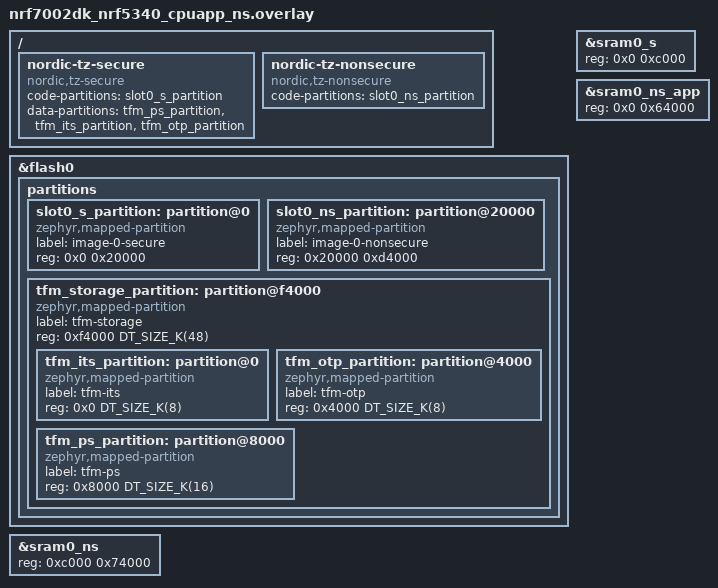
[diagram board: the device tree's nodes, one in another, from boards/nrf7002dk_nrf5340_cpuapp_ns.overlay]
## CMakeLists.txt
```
#
# Copyright (c) 2020 Nordic Semiconductor
#
# SPDX-License-Identifier: LicenseRef-Nordic-5-Clause
#

cmake_minimum_required(VERSION 3.20.0)

find_package(Zephyr REQUIRED HINTS $ENV{ZEPHYR_BASE})
project(https_client)

# Generate hex files from pem files
set(gen_dir ${CMAKE_CURRENT_BINARY_DIR}/certs)
zephyr_include_directories(${gen_dir})
generate_inc_file_for_target(
    app
    cert/example_com_ca.pem
    ${gen_dir}/example_com_ca.pem.inc
    )

# NORDIC SDK APP START
target_sources(app PRIVATE src/main.c)
# NORDIC SDK APP END
```

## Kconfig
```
#
# Copyright (c) 2021 Nordic Semiconductor ASA
#
# SPDX-License-Identifier: LicenseRef-Nordic-5-Clause
#

menu "HTTPS client sample"

config SAMPLE_TFM_MBEDTLS
	bool "Use TF-M and MbedTLS"
	depends on NRF_MODEM_LIB
	help
	  Use TF-M and MbedTLS in this sample instead of using
	  the offloaded TLS stack in the modem.

config HTTPS_HOSTNAME
	string "HTTPS hostname"
	default "example.com"

endmenu

# Default the TLS credentials backend by build type: NS builds use Protected
# Storage, secure-only builds fall back to the volatile backend. nRF91 keeps
# its own NRF_MODEM backend default.
choice TLS_CREDENTIALS_BACKEND
	default TLS_CREDENTIALS_BACKEND_PROTECTED_STORAGE if BUILD_WITH_TFM && !NRF_MODEM_LIB
endchoice

menu "Zephyr Kernel"
source "Kconfig.zephyr"
endmenu
```

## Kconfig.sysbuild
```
#
# Copyright (c) 2024 Nordic Semiconductor ASA
#
# SPDX-License-Identifier: LicenseRef-Nordic-5-Clause
#

config WIFI_NRF70
	default y if BOARD_NRF7002DK_NRF5340_CPUAPP_NS || \
		BOARD_NRF54L15DK_NRF54L15_CPUAPP || \
		BOARD_NRF54H20DK_NRF54H20_CPUAPP || \
		BOARD_NRF54LM20DK_NRF54LM20A_CPUAPP || \
		BOARD_NRF54LM20DK_NRF54LM20B_CPUAPP

source "share/sysbuild/Kconfig"
```

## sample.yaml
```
sample:
  name: HTTPS client sample
tests:
  sample.net.https_client:
    sysbuild: true
    build_only: true
    integration_platforms:
      - nrf9151dk/nrf9151/ns
      - native_sim
    platform_allow:
      - nrf9151dk/nrf9151/ns
      - native_sim
    tags:
      - ci_build
      - sysbuild
      - ci_samples_net
  sample.net.https_client.wifi:
    sysbuild: true
    build_only: true
    integration_platforms:
      - nrf7002dk/nrf5340/cpuapp/ns
      - nrf7120dk/nrf7120/cpuapp/ns
    platform_allow:
      - nrf7002dk/nrf5340/cpuapp/ns
      - nrf7120dk/nrf7120/cpuapp/ns
    tags:
      - ci_build
      - sysbuild
      - ci_samples_net
    extra_args:
      - https_client_EXTRA_CONF_FILE="wifi.conf"
  sample.net.https_client.lte.tfm-mbedtls:
    sysbuild: true
    build_only: true
    extra_args: EXTRA_CONF_FILE="overlay-tfm-nrf91.conf"
    integration_platforms:
      - nrf9151dk/nrf9151/ns
    platform_allow:
      - nrf9151dk/nrf9151/ns
    tags:
      - ci_build
      - sysbuild
      - ci_samples_net
  sample.net.https_client.lte.pdn-ipv4:
    sysbuild: true
    build_only: true
    extra_args: EXTRA_CONF_FILE="overlay-pdn-nrf91-ipv4.conf"
    integration_platforms:
      - nrf9151dk/nrf9151/ns
    platform_allow:
      - nrf9151dk/nrf9151/ns
    tags:
      - ci_build
      - sysbuild
      - ci_samples_net
  sample.net.https_client.nrf54l15_nrf7002eb2.wifi:
    sysbuild: true
    build_only: true
    integration_platforms:
      - nrf54l15dk/nrf54l15/cpuapp
    platform_allow:
      - nrf54l15dk/nrf54l15/cpuapp
    tags:
      - ci_build
      - sysbuild
      - ci_samples_net
    extra_args:
      - https_client_SHIELD="nrf7002eb2"
      - https_client_SNIPPET="nrf70-wifi;wifi-credentials"
      - https_client_EXTRA_CONF_FILE="wifi.conf"
  sample.net.https_client.nrf54lm20_nrf7002eb2.wifi:
    sysbuild: true
    build_only: true
    integration_platforms:
      - nrf54lm20dk/nrf54lm20a/cpuapp
      - nrf54lm20dk/nrf54lm20b/cpuapp
    platform_allow:
      - nrf54lm20dk/nrf54lm20a/cpuapp
      - nrf54lm20dk/nrf54lm20b/cpuapp
    tags:
      - ci_build
      - sysbuild
      - ci_samples_net
    extra_args:
      - https_client_SHIELD="nrf7002eb2"
      - https_client_SNIPPET=wifi-credentials
      - https_client_EXTRA_CONF_FILE="wifi.conf"
```

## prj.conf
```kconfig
#
# Copyright (c) 2023 Nordic Semiconductor ASA
#
# SPDX-License-Identifier: LicenseRef-Nordic-5-Clause
#

# General
CONFIG_HEAP_MEM_POOL_SIZE=1280
CONFIG_MAIN_STACK_SIZE=4096

# Logging
CONFIG_LOG=y

# Network
CONFIG_NETWORKING=y
CONFIG_NET_SOCKETS=y
CONFIG_POSIX_API=y
CONFIG_NET_IPV4=y
CONFIG_NET_IPV6=y
CONFIG_NET_CONNECTION_MANAGER=y
```

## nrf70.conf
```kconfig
#
# Copyright (c) 2026 Nordic Semiconductor ASA
#
# SPDX-License-Identifier: LicenseRef-Nordic-5-Clause
#

# nRF70 Wi-Fi driver tuning (external nRF7002 companion). Kept out of wifi.conf so it is
# only applied on nRF70 targets; the integrated nRF71 (nrf7120) uses its board conf instead.
CONFIG_NRF70_RX_NUM_BUFS=16
CONFIG_NRF70_MAX_TX_AGGREGATION=4
CONFIG_NRF70_BH_WQ_STACK_SIZE=2300
```

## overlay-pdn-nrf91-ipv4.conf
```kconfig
#
# Copyright (c) 2023 Nordic Semiconductor ASA
#
# SPDX-License-Identifier: LicenseRef-Nordic-5-Clause
#

CONFIG_LTE_LC_PDN_DEFAULTS_OVERRIDE=y
CONFIG_LTE_LC_PDN_DEFAULT_FAM_IPV4=y
```

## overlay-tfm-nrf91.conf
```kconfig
#
# Copyright (c) 2023 Nordic Semiconductor ASA
#
# SPDX-License-Identifier: LicenseRef-Nordic-5-Clause
#

CONFIG_SAMPLE_TFM_MBEDTLS=y

# TFM configuration
CONFIG_TFM_PROFILE_TYPE_NOT_SET=y

# MbedTLS and security
CONFIG_MBEDTLS=y
CONFIG_NET_SOCKETS_SOCKOPT_TLS=y
CONFIG_MBEDTLS_ENABLE_HEAP=y
CONFIG_MBEDTLS_SSL_IN_CONTENT_LEN=4096
CONFIG_MBEDTLS_SSL_OUT_CONTENT_LEN=4096
CONFIG_MBEDTLS_SSL_SERVER_NAME_INDICATION=y
CONFIG_MBEDTLS_HEAP_SIZE=32768
CONFIG_MBEDTLS_DECLARE_PRIVATE_IDENTIFIERS=y
CONFIG_MBEDTLS_MD_C=y
CONFIG_MBEDTLS_HMAC_DRBG_C=y
CONFIG_PSA_WANT_ALG_SHA_256=y
CONFIG_PSA_WANT_KEY_TYPE_ECC_KEY_PAIR_IMPORT=y
CONFIG_PSA_WANT_KEY_TYPE_ECC_KEY_PAIR_EXPORT=y
CONFIG_PSA_WANT_KEY_TYPE_ECC_KEY_PAIR_GENERATE=y
CONFIG_PSA_WANT_KEY_TYPE_ECC_KEY_PAIR_DERIVE=y
CONFIG_MBEDTLS_CTR_DRBG_C=y
CONFIG_PSA_WANT_KEY_TYPE_AES=y
CONFIG_PSA_WANT_ALG_CBC_PKCS7=y
CONFIG_PSA_WANT_ALG_CBC_NO_PADDING=y
CONFIG_PSA_WANT_ALG_CTR=y
CONFIG_MBEDTLS_ENTROPY_C=y

CONFIG_PSA_WANT_ALG_RSA_PKCS1V15_CRYPT=y
CONFIG_PSA_WANT_ALG_RSA_PKCS1V15_SIGN=y
CONFIG_PSA_WANT_ALG_RSA_PSS=y
CONFIG_PSA_WANT_ALG_RSA_OAEP=y
CONFIG_PSA_WANT_RSA_KEY_SIZE_2048=y
CONFIG_PSA_WANT_KEY_TYPE_RSA_KEY_PAIR_IMPORT=y
CONFIG_PSA_WANT_KEY_TYPE_RSA_KEY_PAIR_EXPORT=y
CONFIG_PSA_WANT_KEY_TYPE_RSA_KEY_PAIR_DERIVE=y
CONFIG_PSA_WANT_KEY_TYPE_RSA_KEY_PAIR_GENERATE=y

CONFIG_MBEDTLS_PEM_PARSE_C=y
CONFIG_PSA_WANT_KEY_TYPE_RSA_KEY_PAIR_IMPORT=y
CONFIG_PSA_WANT_KEY_TYPE_RSA_KEY_PAIR_EXPORT=y
CONFIG_PSA_WANT_KEY_TYPE_RSA_KEY_PAIR_GENERATE=y
# Set MPI (Multiple Precision Integer) size limit to 512 bytes for handling of 4 kb certificates
# in cryptographic operations.
CONFIG_MBEDTLS_MPI_MAX_SIZE=512
# ECDH/ECDSA are needed for TLS handshake
CONFIG_PSA_WANT_ALG_ECDH=y
CONFIG_PSA_WANT_ALG_ECDSA=y
CONFIG_PSA_CRYPTO=y
CONFIG_PSA_CRYPTO_DRIVER_CC3XX=y
# The CC3xx (CryptoCell) PSA driver fails ECDSA *verification* of an imported
# public key (returns PSA_ERROR_INVALID_ARGUMENT), which breaks TLS certificate
# and ServerKeyExchange verification. Disable the CC3xx asymmetric-signature
# driver so ECDSA verify is serviced by the Oberon software driver instead.
CONFIG_PSA_USE_CC3XX_ASYMMETRIC_SIGNATURE_DRIVER=n
CONFIG_PSA_WANT_ALG_SHA_1=y
# SHA-384 is required to verify the ecdsa-with-SHA384 signature on the
# intermediate CA in example.com's chain (and for AES_256_GCM_SHA384 PRF)
CONFIG_PSA_WANT_ALG_SHA_384=y
CONFIG_PSA_WANT_ALG_RSA_PKCS1V15_CRYPT=y
CONFIG_PSA_WANT_ALG_RSA_PKCS1V15_SIGN=y
CONFIG_PSA_WANT_KEY_TYPE_RSA_PUBLIC_KEY=y
CONFIG_PSA_WANT_ECC_SECP_R1_256=y
CONFIG_PSA_WANT_ECC_SECP_R1_384=y

# RSA requires that at least one key size is enabled
CONFIG_PSA_WANT_RSA_KEY_SIZE_1024=y

# Modem key management needs to be set to n, if not the certificate are provisioned to the modem
CONFIG_MODEM_KEY_MGMT=n
```

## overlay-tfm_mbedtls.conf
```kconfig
#
# Copyright (c) 2023 Nordic Semiconductor ASA
#
# SPDX-License-Identifier: LicenseRef-Nordic-5-Clause
#

CONFIG_SAMPLE_TFM_MBEDTLS=y

# TFM configuration
CONFIG_TFM_PROFILE_TYPE_NOT_SET=y

# MbedTLS and security
CONFIG_MBEDTLS=y
CONFIG_NET_SOCKETS_SOCKOPT_TLS=y
CONFIG_MBEDTLS_ENABLE_HEAP=y
CONFIG_MBEDTLS_SSL_IN_CONTENT_LEN=4096
CONFIG_MBEDTLS_SSL_OUT_CONTENT_LEN=4096
CONFIG_MBEDTLS_HEAP_SIZE=32768
CONFIG_MBEDTLS_RSA_C=y
CONFIG_MBEDTLS_TLS_LIBRARY=y
CONFIG_MBEDTLS_X509_LIBRARY=y
CONFIG_MBEDTLS_PKCS1_V15=y
CONFIG_NRF_SECURITY_ADVANCED=y
CONFIG_NORDIC_SECURITY_BACKEND=y
CONFIG_PSA_CRYPTO_DRIVER_CC3XX=y
CONFIG_PSA_WANT_ALG_SHA_1=y
CONFIG_PSA_WANT_ALG_RSA_PKCS1V15_CRYPT=y
CONFIG_PSA_WANT_ALG_RSA_PKCS1V15_SIGN=y
CONFIG_PSA_WANT_KEY_TYPE_RSA_PUBLIC_KEY=y

# RSA requires that at least one key size is enabled
CONFIG_PSA_WANT_RSA_KEY_SIZE_1024=y

# Modem key management needs to be set to n, if not the certificate are provisioned to the modem
CONFIG_MODEM_KEY_MGMT=n
```

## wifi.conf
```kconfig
#
# Copyright (c) 2026 Nordic Semiconductor ASA
#
# SPDX-License-Identifier: LicenseRef-Nordic-5-Clause
#

# Common Wi-Fi + networking + TLS configuration shared by all Wi-Fi builds of
# this sample (nRF70 and nRF71).

# Logging
CONFIG_NET_LOG=y

# Wi-Fi stack
CONFIG_WIFI=y
CONFIG_WIFI_NM_WPA_SUPPLICANT=y
CONFIG_NET_L2_ETHERNET=y

# Wi-Fi credentials. TF-M (_ns) builds use PSA Protected Storage. Non-TF-M
# builds use the Settings subsystem, requiring the wifi-credentials snippet.
CONFIG_WIFI_CREDENTIALS=y

# Zephyr NET Connection Manager Connectivity layer.
CONFIG_L2_WIFI_CONNECTIVITY=y
CONFIG_L2_WIFI_CONNECTIVITY_AUTO_CONNECT=n
CONFIG_L2_WIFI_CONNECTIVITY_AUTO_DOWN=n

# Networking
CONFIG_NET_NATIVE=y
CONFIG_NET_SOCKETS=y
CONFIG_NET_SOCKETS_OFFLOAD=n
CONFIG_NET_IPV6=y
CONFIG_NET_UDP=y
CONFIG_NET_TCP=y
CONFIG_NET_DHCPV4=y
CONFIG_NET_CONTEXT_SNDTIMEO=y
CONFIG_NET_CONTEXT_RCVTIMEO=y

# DNS
CONFIG_DNS_RESOLVER=y
CONFIG_NET_SOCKETS_DNS_TIMEOUT=30000
CONFIG_DNS_RESOLVER_AI_MAX_ENTRIES=4

# Wi-Fi shell
CONFIG_SHELL=y
CONFIG_SHELL_CMDS_RESIZE=n
CONFIG_NET_L2_WIFI_SHELL=y

# POSIX API memory optimizations
CONFIG_POSIX_NETWORKING=y
CONFIG_POSIX_FD_MGMT=n
CONFIG_POSIX_MESSAGE_PASSING=n
CONFIG_POSIX_THREAD_THREADS_MAX=0

# Network resource sizing (workload-specific for this sample)
CONFIG_NET_MAX_CONN=8
CONFIG_NET_MAX_CONTEXTS=6
CONFIG_ZVFS_POLL_MAX=8
CONFIG_NET_PKT_TX_COUNT=6
CONFIG_NET_PKT_RX_COUNT=6
CONFIG_NET_BUF_TX_COUNT=12
CONFIG_NET_BUF_RX_COUNT=6

# NET sockets TLS
CONFIG_NET_SOCKETS_ENABLE_DTLS=n
CONFIG_NET_SOCKETS_TLS_MAX_CONTEXTS=2
CONFIG_NET_SOCKETS_SOCKOPT_TLS=y
CONFIG_TLS_CREDENTIALS=y
# Persist TLS credentials across reboots.
CONFIG_TLS_CREDENTIALS_BACKEND_PROTECTED_STORAGE=y

# mbedTLS
CONFIG_MBEDTLS=y
CONFIG_MBEDTLS_ENABLE_HEAP=y
# Shrink the TLS record buffers and negotiate the smaller size with the peer
# (RFC 6066 max_fragment_length) so servers don't send records larger than
# what we can receive. This cuts mbedTLS's heap requirement by roughly 24KB
# (measured) without risking handshake failures against servers that send
# larger default-sized records (e.g. bigger certificate chains).
CONFIG_MBEDTLS_SSL_IN_CONTENT_LEN=4096
CONFIG_MBEDTLS_SSL_OUT_CONTENT_LEN=4096
CONFIG_MBEDTLS_SSL_MAX_FRAGMENT_LENGTH=y
CONFIG_MBEDTLS_HEAP_SIZE=49152
CONFIG_MBEDTLS_SSL_KEEP_PEER_CERTIFICATE=n
CONFIG_MBEDTLS_SSL_SERVER_NAME_INDICATION=y
CONFIG_MBEDTLS_PEM_PARSE_C=y
CONFIG_MBEDTLS_CIPHERSUITE_TLS_ECDHE_RSA_WITH_AES_128_CBC_SHA256=y
CONFIG_MBEDTLS_CIPHERSUITE_TLS_ECDHE_ECDSA_WITH_AES_256_GCM_SHA384=y
# P-384 for the example.com CA cert (EC P-384 public key). P-256 (server certs and
# ECDHE) and ECDSA sig verify are already pulled in by the ECDHE_ECDSA ciphersuite above.
CONFIG_PSA_WANT_ECC_SECP_R1_384=y
# pk_wrap.c uses PSA_ALG_ECDSA_ANY (pre-hashed ECDSA) for X.509 certificate chain
# verification; without this the PSA core rejects psa_import_key for the CA cert's
# public key and the handshake fails with MBEDTLS_ERR_SSL_FEATURE_UNAVAILABLE.
CONFIG_PSA_WANT_ALG_ECDSA=y
CONFIG_PSA_WANT_KEY_TYPE_ECC_KEY_PAIR_DERIVE=y
# PSA_WANT_ALG_CHACHA20_POLY1305 is auto-enabled (CRACEN HW). The server may pick this
# cipher; psa_import_key(PSA_KEY_TYPE_CHACHA20) then fails unless the key type is also enabled.
CONFIG_PSA_WANT_KEY_TYPE_CHACHA20=y

# Stack sizes
CONFIG_MAIN_STACK_SIZE=8192
CONFIG_SHELL_STACK_SIZE=6144
CONFIG_SYSTEM_WORKQUEUE_STACK_SIZE=4096
CONFIG_NET_CONNECTION_MANAGER_MONITOR_STACK_SIZE=5000
CONFIG_NET_TX_STACK_SIZE=4096
CONFIG_NET_RX_STACK_SIZE=4096

# Heap sizes
CONFIG_HEAP_MEM_POOL_IGNORE_MIN=y
CONFIG_HEAP_MEM_POOL_SIZE=37000
CONFIG_NRF_WIFI_DATA_HEAP_SIZE=32768

# Floating-point printf support (Wi-Fi shell prints PHY TX rate as %f)
CONFIG_CBPRINTF_FP_SUPPORT=y
```

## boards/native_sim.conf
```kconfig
#
# Copyright (c) 2024 Nordic Semiconductor ASA
#
# SPDX-License-Identifier: LicenseRef-Nordic-5-Clause
#

# Networking config
CONFIG_NETWORKING=y
CONFIG_NET_CONFIG_SETTINGS=y
CONFIG_NET_CONNECTION_MANAGER=y
CONFIG_NET_IPV4=y
CONFIG_NET_IPV6=y
CONFIG_NET_TCP=y
CONFIG_NET_UDP=y
CONFIG_NET_SOCKETS=y
CONFIG_POSIX_API=y

# TLS networking
CONFIG_NET_SOCKETS_ENABLE_DTLS=n
CONFIG_NET_SOCKETS_TLS_MAX_CONTEXTS=2
CONFIG_NET_SOCKETS_SOCKOPT_TLS=y

# TLS configuration
CONFIG_MBEDTLS=y
CONFIG_MBEDTLS_ENABLE_HEAP=y
CONFIG_MBEDTLS_HEAP_SIZE=40000
CONFIG_MBEDTLS_SSL_MAX_CONTENT_LEN=7168
CONFIG_MBEDTLS_PEM_PARSE_C=y
CONFIG_MBEDTLS_PEM_WRITE_C=y
CONFIG_MBEDTLS_CIPHERSUITE_TLS_ECDHE_RSA_WITH_AES_128_CBC_SHA256=y
CONFIG_MBEDTLS_CIPHERSUITE_TLS_ECDHE_ECDSA_WITH_AES_256_GCM_SHA384=y
CONFIG_MBEDTLS_SSL_SERVER_NAME_INDICATION=y
CONFIG_PSA_WANT_ECC_SECP_R1_384=y

# DNS
CONFIG_DNS_RESOLVER=y
CONFIG_DNS_SERVER_IP_ADDRESSES=y
CONFIG_DNS_RESOLVER_MAX_SERVERS=2
CONFIG_DNS_SERVER1="8.8.8.8"
```

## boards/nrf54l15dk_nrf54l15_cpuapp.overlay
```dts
/*
 * Copyright (c) 2024 Nordic Semiconductor ASA
 *
 * SPDX-License-Identifier: LicenseRef-Nordic-5-Clause
 */

/delete-node/ &boot_partition;
/delete-node/ &slot0_partition;
/delete-node/ &slot1_partition;
/delete-node/ &storage_partition;

&rram_controller {
	/delete-node/ cpuflpr_sram;
	/delete-node/ cpuflpr_rram;
};

/* Adjust the cpuapp_sram to include the freed up cpuflpr_sram */
&cpuapp_sram {
	reg = <0x20000000 DT_SIZE_K(256)>;
	ranges = <0x0 0x20000000 0x20040000>;
};

/* Adjust the cpuapp_rram to include the freed up cpuflpr_rram */
&cpuapp_rram {
	reg = <0x0 DT_SIZE_K(1524)>;

	partitions {
		slot0_partition: partition@0 {
			compatible = "zephyr,mapped-partition";
			label = "image-0";
			reg = <0x0 0x17b000>;
		};

		storage_partition: partition@17b000 {
			compatible = "zephyr,mapped-partition";
			label = "storage";
			reg = <0x17b000 0x2000>;
		};
	};
};
```

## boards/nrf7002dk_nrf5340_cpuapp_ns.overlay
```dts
/*
 * Copyright (c) 2026 Nordic Semiconductor ASA
 *
 * SPDX-License-Identifier: LicenseRef-Nordic-5-Clause
 */

/delete-node/ &boot_partition;
/delete-node/ &slot0_partition;
/delete-node/ &slot1_partition;
/delete-node/ &tfm_its_partition;
/delete-node/ &tfm_otp_partition;
/delete-node/ &tfm_ps_partition;
/delete-node/ &storage_partition;

&flash0 {
	partitions {
		slot0_s_partition: partition@0 {
			compatible = "zephyr,mapped-partition";
			label = "image-0-secure";
			reg = <0x0 0x20000>;
		};

		slot0_ns_partition: partition@20000 {
			compatible = "zephyr,mapped-partition";
			label = "image-0-nonsecure";
			reg = <0x20000 0xd4000>;
		};

		tfm_storage_partition: partition@f4000 {
			compatible = "zephyr,mapped-partition";
			label = "tfm-storage";
			reg = <0xf4000 DT_SIZE_K(48)>;
			ranges = <0x0 0xf4000 DT_SIZE_K(48)>;
			#address-cells = <1>;
			#size-cells = <1>;

			tfm_its_partition: partition@0 {
				compatible = "zephyr,mapped-partition";
				label = "tfm-its";
				reg = <0x0 DT_SIZE_K(8)>;
			};

			tfm_otp_partition: partition@4000 {
				compatible = "zephyr,mapped-partition";
				label = "tfm-otp";
				reg = <0x4000 DT_SIZE_K(8)>;
			};

			tfm_ps_partition: partition@8000 {
				compatible = "zephyr,mapped-partition";
				label = "tfm-ps";
				reg = <0x8000 DT_SIZE_K(16)>;
			};
		};
	};
};

/*
 * TrustZone SRAM split from devicetree (region_defs.h for TF-M). The secure image uses
 * 48 KiB (0xc000) at the base of cpuapp SRAM (&sram0_s); NS RAM begins at 0x20000000 + 0xc000.
 * &sram0_ns spans 0x74000 bytes; &sram0_ns_app is 0x64000 because the top 0x10000 (64 KiB)
 * within that NS window is sram0_shared for application/network-core IPC
 * (nrf5340_shared_sram_partition.dtsi), i.e. 0x64000 + 0x10000 == 0x74000.
 */
&sram0_s {
	reg = <0x0 0xc000>;
};

&sram0_ns {
	reg = <0xc000 0x74000>;
	ranges = <0x0 0xc000 0x74000>;
};

&sram0_ns_app {
	reg = <0x0 0x64000>;
};

/ {
	/delete-node/ nordic-tz-secure;
	/delete-node/ nordic-tz-nonsecure;

	nordic-tz-secure {
		compatible = "nordic,tz-secure";
		code-partitions = <&slot0_s_partition>;
		data-partitions = <&tfm_ps_partition>,
				  <&tfm_its_partition>,
				  <&tfm_otp_partition>;
	};

	nordic-tz-nonsecure {
		compatible = "nordic,tz-nonsecure";
		code-partitions = <&slot0_ns_partition>;
	};
};
```

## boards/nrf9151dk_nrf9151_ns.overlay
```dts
/*
 * Copyright (c) 2024 Nordic Semiconductor ASA
 *
 * SPDX-License-Identifier: LicenseRef-Nordic-5-Clause
 */

/* Increase UART baudrate to 1Mbaud for high-speed logging with mbedTLS debug */
&uart0 {
	// current-speed = <1000000>;
};
```

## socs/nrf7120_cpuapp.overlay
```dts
/*
 * Copyright (c) 2026 Nordic Semiconductor ASA
 *
 * SPDX-License-Identifier: LicenseRef-Nordic-5-Clause
 */

#include <vendor/nordic/wifi/nrf7120_wifi_patch_0_1_0.dtsi>
```

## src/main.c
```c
/*
 * Copyright (c) 2020 Nordic Semiconductor ASA
 *
 * SPDX-License-Identifier: LicenseRef-Nordic-5-Clause
 */

#include <string.h>
#include <zephyr/kernel.h>
#include <stdlib.h>
#include <zephyr/net/socket.h>
#include <zephyr/net/conn_mgr_connectivity.h>
#include <zephyr/net/tls_credentials.h>

#if defined(CONFIG_POSIX_API)
#include <zephyr/posix/arpa/inet.h>
#include <zephyr/posix/netdb.h>
#include <zephyr/posix/unistd.h>
#include <zephyr/posix/sys/socket.h>
#endif

#if CONFIG_MODEM_KEY_MGMT
#include <modem/modem_key_mgmt.h>
#endif

#define HTTPS_PORT		"443"
#define HTTP_HEAD		\
				"HEAD / HTTP/1.1\r\n"	\
				"Host: " CONFIG_HTTPS_HOSTNAME ":" HTTPS_PORT "\r\n"		\
				"Connection: close\r\n\r\n"

#define HTTP_HEAD_LEN		(sizeof(HTTP_HEAD) - 1)
#define HTTP_HDR_END		"\r\n\r\n"

#define RECV_BUF_SIZE		2048
#define TLS_SEC_TAG		42
#define IP_FAMILY_EVENT_IPV4	BIT(0)
#define IP_FAMILY_EVENT_IPV6	BIT(1)

/* Macros used to subscribe to specific Zephyr NET management events. */
#define L4_EVENT_MASK		(NET_EVENT_L4_CONNECTED | NET_EVENT_L4_DISCONNECTED |	\
				 NET_EVENT_L4_IPV4_CONNECTED | NET_EVENT_L4_IPV4_DISCONNECTED |	\
				 NET_EVENT_L4_IPV6_CONNECTED | NET_EVENT_L4_IPV6_DISCONNECTED)
#define CONN_LAYER_EVENT_MASK	(NET_EVENT_CONN_IF_FATAL_ERROR)

static const char send_buf[] = HTTP_HEAD;
static char recv_buf[RECV_BUF_SIZE];
static K_SEM_DEFINE(network_connected_sem, 0, 1);
static K_EVENT_DEFINE(ip_family_event);
static ATOMIC_DEFINE(network_state, 2);
/* Certificate for `example.com` */
static const char cert[] = {
	#include "example_com_ca.pem.inc"

	/* Null terminate certificate if running Mbed TLS on the application core.
	 * Required by TLS credentials API.
	 */
	IF_ENABLED(CONFIG_TLS_CREDENTIALS, (0x00))
};

enum network_state_flag {
	NETWORK_STATE_IPV4_READY,
	NETWORK_STATE_IPV6_READY,
};

BUILD_ASSERT(sizeof(cert) < KB(4), "Certificate too large");

/* Provision certificate to modem */
int cert_provision(void)
{
	int err;

	printk("Provisioning certificate\n");

#if CONFIG_MODEM_KEY_MGMT
	bool exists;
	int mismatch;

	/* It may be sufficient for you application to check whether the correct
	 * certificate is provisioned with a given tag directly using modem_key_mgmt_cmp().
	 * Here, for the sake of the completeness, we check that a certificate exists
	 * before comparing it with what we expect it to be.
	 */
	err = modem_key_mgmt_exists(TLS_SEC_TAG, MODEM_KEY_MGMT_CRED_TYPE_CA_CHAIN, &exists);
	if (err) {
		printk("Failed to check for certificates err %d\n", err);
		return err;
	}

	if (exists) {
		mismatch = modem_key_mgmt_cmp(TLS_SEC_TAG, MODEM_KEY_MGMT_CRED_TYPE_CA_CHAIN, cert,
					      sizeof(cert));
		if (!mismatch) {
			printk("Certificate match\n");
			return 0;
		}

		printk("Certificate mismatch\n");
		err = modem_key_mgmt_delete(TLS_SEC_TAG, MODEM_KEY_MGMT_CRED_TYPE_CA_CHAIN);
		if (err) {
			printk("Failed to delete existing certificate, err %d\n", err);
		}
	}

	printk("Provisioning certificate to the modem\n");

	/*  Provision certificate to the modem */
	err = modem_key_mgmt_write(TLS_SEC_TAG, MODEM_KEY_MGMT_CRED_TYPE_CA_CHAIN, cert,
				   sizeof(cert));
	if (err) {
		printk("Failed to provision certificate, err %d\n", err);
		return err;
	}
#else /* CONFIG_MODEM_KEY_MGMT */
	err = tls_credential_add(TLS_SEC_TAG,
				 TLS_CREDENTIAL_CA_CERTIFICATE,
				 cert,
				 sizeof(cert));
	if (err == -EEXIST) {
		printk("CA certificate already exists, sec tag: %d\n", TLS_SEC_TAG);
	} else if (err < 0) {
		printk("Failed to register CA certificate: %d\n", err);
		return err;
	}
#endif /* !CONFIG_MODEM_KEY_MGMT */

	return 0;
}


/* Setup TLS options on a given socket */
int tls_setup(int fd)
{
	int err;
	int verify;

	/* Security tag that we have provisioned the certificate with */
	const sec_tag_t tls_sec_tag[] = {
		TLS_SEC_TAG,
	};

	/* Set up TLS peer verification */
	enum {
		NONE = 0,
		OPTIONAL = 1,
		REQUIRED = 2,
	};

	verify = REQUIRED;

	err = setsockopt(fd, SOL_TLS, TLS_PEER_VERIFY, &verify, sizeof(verify));
	if (err) {
		printk("Failed to setup peer verification, err %d\n", errno);
		return err;
	}

	/* Associate the socket with the security tag
	 * we have provisioned the certificate with.
	 */
	err = setsockopt(fd, SOL_TLS, TLS_SEC_TAG_LIST, tls_sec_tag, sizeof(tls_sec_tag));
	if (err) {
		printk("Failed to setup TLS sec tag, err %d\n", errno);
		return err;
	}

	err = setsockopt(fd, SOL_TLS, TLS_HOSTNAME,
			CONFIG_HTTPS_HOSTNAME,
			sizeof(CONFIG_HTTPS_HOSTNAME) - 1);
	if (err) {
		printk("Failed to setup TLS hostname, err %d\n", errno);
		return err;
	}
	return 0;
}

static void on_net_event_l4_disconnected(void)
{
	printk("Disconnected from the network\n");
}

static void on_net_event_l4_connected(void)
{
	k_sem_give(&network_connected_sem);
}

static void l4_event_handler(uint64_t event, struct net_if *iface, void *info,
			     size_t info_length, void *user_data)
{
	switch (event) {
	case NET_EVENT_L4_CONNECTED:
		printk("Network connectivity established and IP address assigned\n");
		on_net_event_l4_connected();
		break;
	case NET_EVENT_L4_DISCONNECTED:
		printk("Network connectivity lost\n");
		on_net_event_l4_disconnected();
		break;
	case NET_EVENT_L4_IPV4_CONNECTED:
		atomic_set_bit(network_state, NETWORK_STATE_IPV4_READY);
		k_event_post(&ip_family_event, IP_FAMILY_EVENT_IPV4);
		printk("IPv4 connectivity established\n");
		break;
	case NET_EVENT_L4_IPV4_DISCONNECTED:
		printk("IPv4 connectivity lost\n");
		atomic_clear_bit(network_state, NETWORK_STATE_IPV4_READY);
		k_event_clear(&ip_family_event, IP_FAMILY_EVENT_IPV4);
		break;
	case NET_EVENT_L4_IPV6_CONNECTED:
		atomic_set_bit(network_state, NETWORK_STATE_IPV6_READY);
		k_event_post(&ip_family_event, IP_FAMILY_EVENT_IPV6);
		printk("IPv6 connectivity established\n");
		break;
	case NET_EVENT_L4_IPV6_DISCONNECTED:
		printk("IPv6 connectivity lost\n");
		atomic_clear_bit(network_state, NETWORK_STATE_IPV6_READY);
		k_event_clear(&ip_family_event, IP_FAMILY_EVENT_IPV6);
		break;
	default:
		break;
	}
}

static void connectivity_event_handler(uint64_t event, struct net_if *iface, void *info,
				       size_t info_length, void *user_data)
{
	if (event == NET_EVENT_CONN_IF_FATAL_ERROR) {
		printk("Fatal error received from the connectivity layer\n");
		return;
	}
}

/* Registered statically to not miss events raised before main() */
NET_MGMT_REGISTER_EVENT_HANDLER(l4_events, L4_EVENT_MASK, l4_event_handler, NULL);
NET_MGMT_REGISTER_EVENT_HANDLER(conn_events, CONN_LAYER_EVENT_MASK, connectivity_event_handler,
				NULL);

static bool ipv4_ready(void)
{
	return atomic_test_bit(network_state, NETWORK_STATE_IPV4_READY);
}

static bool ipv6_ready(void)
{
	return atomic_test_bit(network_state, NETWORK_STATE_IPV6_READY);
}

static bool family_ready(int family)
{
	if (family == AF_INET) {
		return ipv4_ready();
	}

	if (family == AF_INET6) {
		return ipv6_ready();
	}

	return false;
}

static int wait_for_family_ready_event(int family)
{
	const uint32_t family_event = (family == AF_INET) ? IP_FAMILY_EVENT_IPV4 :
					IP_FAMILY_EVENT_IPV6;
	int events;

	printk("Waiting for local %s address event\n", family == AF_INET ? "IPv4" : "IPv6");
	events = k_event_wait(&ip_family_event, family_event, false, K_FOREVER);
	if (events == 0) {
		printk("Failed to wait for local %s address event\n",
		       family == AF_INET ? "IPv4" : "IPv6");
		return -EIO;
	}

	if (!family_ready(family)) {
		printk("Local %s address is not ready\n", family == AF_INET ? "IPv4" : "IPv6");
		return -EIO;
	}

	printk("Local %s address is now ready\n", family == AF_INET ? "IPv4" : "IPv6");

	return 0;
}

static int connect_to_family(struct addrinfo *res, int family, int *last_err)
{
	int fd;
	int err;
	uint16_t peer_port;
	char peer_addr[INET6_ADDRSTRLEN];

	for (struct addrinfo *entry = res; entry != NULL; entry = entry->ai_next) {
		const void *addr_ptr;

		if (entry->ai_family != family) {
			continue;
		}

		if (entry->ai_family == AF_INET6) {
			addr_ptr = &((const struct sockaddr_in6 *)entry->ai_addr)->sin6_addr;
			peer_port = ntohs(((const struct sockaddr_in6 *)entry->ai_addr)->sin6_port);
		} else {
			addr_ptr = &((const struct sockaddr_in *)entry->ai_addr)->sin_addr;
			peer_port = ntohs(((const struct sockaddr_in *)entry->ai_addr)->sin_port);
		}

		if (inet_ntop(entry->ai_family, addr_ptr, peer_addr, sizeof(peer_addr)) == NULL) {
			(void)snprintf(peer_addr, sizeof(peer_addr), "<inet_ntop err %d>", errno);
		}

		printk("Resolved %s (%s)\n", peer_addr, net_family2str(entry->ai_family));

		if (IS_ENABLED(CONFIG_SAMPLE_TFM_MBEDTLS)) {
			fd = socket(entry->ai_family, SOCK_STREAM | SOCK_NATIVE_TLS,
				    IPPROTO_TLS_1_2);
		} else {
			fd = socket(entry->ai_family, SOCK_STREAM, IPPROTO_TLS_1_2);
		}
		if (fd == -1) {
			*last_err = errno;
			printk("Failed to open socket for %s\n", peer_addr);
			continue;
		}

		err = tls_setup(fd);
		if (err) {
			*last_err = errno;
			(void)close(fd);
			continue;
		}

		printk("Connecting to %s:%d (%s)\n", CONFIG_HTTPS_HOSTNAME, peer_port, peer_addr);
		err = connect(fd, entry->ai_addr, entry->ai_addrlen);
		if (err) {
			*last_err = errno;
			printk("connect() failed for %s, err: %d. Will try another IP.\n",
			       peer_addr, *last_err);
			(void)close(fd);
			continue;
		}

		return fd;
	}

	return -1;
}

static int connect_to_server(struct addrinfo *res, int *last_err)
{
	int first_family = AF_UNSPEC;
	int second_family = AF_UNSPEC;
	int fd = -1;

	for (struct addrinfo *entry = res; entry != NULL; entry = entry->ai_next) {
		if (IS_ENABLED(CONFIG_NET_IPV4) && entry->ai_family == AF_INET) {
			first_family = AF_INET;
		} else if (IS_ENABLED(CONFIG_NET_IPV6) && entry->ai_family == AF_INET6) {
			second_family = AF_INET6;
		}
	}

	if (first_family == AF_INET) {
		/* If IPv4 is resolved and compiled in but not ready, then swap first and second
		 * families to start with IPv6 if it is resolved and compiled in, otherwise, keep
		 * IPv4 and wait for IP address.
		 */
		if (!ipv4_ready() && second_family == AF_INET6) {
			first_family = AF_INET6;
			second_family = AF_INET;
		}
	} else {
		/* If IPv4 is not resolved or compiled in, select second family. Don't set AF_UNSPEC
		 * directly, because second_family can be resolved to AF_UNSPEC if IPv6 is not
		 * compiled in.
		 */
		first_family = second_family;
	}

	/* This happens if resolved families and compiled families don't match. For example, if IPv6
	 * is resolved but not compiled in.
	 */
	if (first_family == AF_UNSPEC) {
		printk("No supported address families found\n");
		return -1;
	}

	/* It is possible that the first family is not ready yet if resolved families don't match
	 * to device family, which device got first. Therefore we need to wait for the other family
	 * to be ready.
	 */
	if (!family_ready(first_family)) {
		int err;

		err = wait_for_family_ready_event(first_family);
		if (err != 0) {
			printk("Failed to wait for the first family ready event, err %d\n", err);
			return -1;
		}
	}

	fd = connect_to_family(res, first_family, last_err);
	if (fd >= 0) {
		return fd;
	}

	/* Try the second family. */
	if (second_family == AF_UNSPEC) {
		return fd;
	}

	if (!family_ready(second_family)) {
		int err;

		err = wait_for_family_ready_event(second_family);
		if (err != 0) {
			printk("Failed to wait for the second family ready event, err %d\n", err);
			return -1;
		}
	}

	fd = connect_to_family(res, second_family, last_err);
	return fd;
}

static void send_http_request(void)
{
	int err;
	int fd = -1;
	char *p;
	int bytes;
	size_t off;
	struct addrinfo *res = NULL;
	struct addrinfo hints = {
		.ai_flags = AI_NUMERICSERV, /* Let getaddrinfo() set port */
		.ai_socktype = SOCK_STREAM,
	};
	int connect_errno = 0;

	printk("Looking up %s\n", CONFIG_HTTPS_HOSTNAME);

	err = getaddrinfo(CONFIG_HTTPS_HOSTNAME, HTTPS_PORT, &hints, &res);
	if (err) {
		connect_errno = errno;
		printk("getaddrinfo() failed, err %d\n", errno);
		goto clean_up;
	}

	fd = connect_to_server(res, &connect_errno);
	if (fd < 0) {
		printk("Failed to connect to any resolved address for %s, last err: %d\n",
		       CONFIG_HTTPS_HOSTNAME, connect_errno);
		goto clean_up;
	}

	off = 0;
	do {
		bytes = send(fd, &send_buf[off], HTTP_HEAD_LEN - off, 0);
		if (bytes < 0) {
			printk("send() failed, err %d\n", errno);
			goto clean_up;
		}
		off += bytes;
	} while (off < HTTP_HEAD_LEN);

	printk("Sent %d bytes\n", off);

	off = 0;
	do {
		bytes = recv(fd, &recv_buf[off], RECV_BUF_SIZE - off, 0);
		if (bytes < 0) {
			printk("recv() failed, err %d\n", errno);
			goto clean_up;
		}
		off += bytes;
	} while (bytes != 0 /* peer closed connection */);

	printk("Received %d bytes\n", off);

	/* Make sure recv_buf is NULL terminated (for safe use with strstr) */
	if (off < sizeof(recv_buf)) {
		recv_buf[off] = '\0';
	} else {
		recv_buf[sizeof(recv_buf) - 1] = '\0';
	}

	/* Print HTTP response */
	p = strstr(recv_buf, "\r\n");
	if (p) {
		off = p - recv_buf;
		recv_buf[off + 1] = '\0';
		printk("\n>\t %s\n\n", recv_buf);
	}

	printk("Finished, closing socket.\n");

clean_up:
	if (res != NULL) {
		freeaddrinfo(res);
	}
	if (fd >= 0) {
		(void)close(fd);
	}
}

int main(void)
{
	int err;

	printk("HTTPS client sample started\n\r");

	printk("Bringing network interface up\n");

	/* Connecting to the configured connectivity layer.
	 * Wi-Fi or LTE depending on the board that the sample was built for.
	 */
	err = conn_mgr_all_if_up(true);
	if (err) {
		printk("conn_mgr_all_if_up, error: %d\n", err);
		return err;
	}

	 /* Provision certificates before connecting to the network */
	err = cert_provision();
	if (err) {
		return 0;
	}

	printk("Connecting to the network\n");

	err = conn_mgr_all_if_connect(true);
	if (err) {
		printk("conn_mgr_all_if_connect, error: %d\n", err);
		return 0;
	}

	k_sem_take(&network_connected_sem, K_FOREVER);

	send_http_request();

	/* A small delay for the TCP connection teardown */
	k_sleep(K_SECONDS(1));

	/* The HTTP transaction is done, take the network connection down */
	err = conn_mgr_all_if_disconnect(true);
	if (err) {
		printk("conn_mgr_all_if_disconnect, error: %d\n", err);
	}

	err = conn_mgr_all_if_down(true);
	if (err) {
		printk("conn_mgr_all_if_down, error: %d\n", err);
	}

	return 0;
}
```

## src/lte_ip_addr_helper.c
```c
/*
 * Copyright (c) 2023 Nordic Semiconductor ASA
 *
 * SPDX-License-Identifier: LicenseRef-Nordic-5-Clause
 */

#include <string.h>
#include <zephyr/device.h>
#include <zephyr/types.h>
#include <zephyr/net/net_if.h>
#include <zephyr/net/net_ip.h>
#include <zephyr/net/socket.h>
#include <zephyr/logging/log.h>
#include <nrf_modem_at.h>

#ifdef CONFIG_POSIX_API
#include <arpa/inet.h>
#endif

#include "lte_ip_addr_helper.h"

LOG_MODULE_REGISTER(ip_addr_helper, 0);

/* Structure that keeps track of the current IP addresses in use. */
static struct ip_addr_helper_data {
#if CONFIG_NET_IPV4
	struct net_in_addr ipv4_addr_current;
	bool ipv4_added;
#endif
#if CONFIG_NET_IPV6
	struct net_in6_addr ipv6_addr_current;
	bool ipv6_added;
#endif
} ctx;

/* @brief Function that obtains either the IPv4 or IPv6 address associated with
 *	  the default PDP context 0.
 *
 * @details Only a single IP family address is written to per call.
 *	    It's expected that only one of the input arguments points to a valid
 *	    buffer when calling this function. The other buffer must be set to NULL.
 *
 * @param [out] addr4 Pointer to a NULL terminated buffer for IPv4 address.
 * @param [out] addr6 Pointer to a NULL terminated buffer for IPv6 address.
 *
 * @returns Length of address string on success, negative value on failure.
 */
static int ip_addr_get(char *addr4, char *addr6)
{
	int ret;
	char tmp[sizeof(struct net_in6_addr)];
	char addr1[NET_IPV6_ADDR_LEN] = { 0 };
#if CONFIG_NET_IPV6
	char addr2[NET_IPV6_ADDR_LEN] = { 0 };
#endif

	if ((!addr4 && !addr6) || (addr4 && addr6)) {
		return -EINVAL;
	}

#if !CONFIG_NET_IPV4
	if (addr4) {
		LOG_ERR("IPv4 address requested when IPv4 is not enabled");
		return -EINVAL;
	}
#endif /* !CONFIG_NET_IPV4 */

#if !CONFIG_NET_IPV6
	if (addr6) {
		LOG_ERR("IPv6 address requested when IPv6 is not enabled");
		return -EINVAL;
	}
#endif /* !CONFIG_NET_IPV6 */

	/* Parse +CGPADDR: <cid>,<PDP_addr_1>,<PDP_addr_2>
	 * PDN type "IP": PDP_addr_1 is <IPv4>, max 16(INET_ADDRSTRLEN)
	 * PDN type "IPV6": PDP_addr_1 is <IPv6>, max 46(INET6_ADDRSTRLEN)
	 * PDN type "IPV4V6": <IPv4>,<IPv6> or <IPV4> or <IPv6>
	 */
#if CONFIG_NET_IPV6
	ret = nrf_modem_at_scanf("AT+CGPADDR=0",
		"+CGPADDR: %*d,\"%46[.:0-9A-F]\",\"%46[:0-9A-F]\"",
		addr1, addr2);
#else
	ret = nrf_modem_at_scanf("AT+CGPADDR=0", "+CGPADDR: %*d,\"%46[.:0-9A-F]\"",
				 addr1);
#endif
	if (ret <= 0) {
		return -EFAULT;
	}

#if CONFIG_NET_IPV4
#ifdef CONFIG_POSIX_API
	if ((addr4 != NULL) && (inet_pton(AF_INET, addr1, tmp) == 1)) {
		strcpy(addr4, addr1);
		return strlen(addr4);
	}
#else
	if ((addr4 != NULL) && (zsock_inet_pton(NET_AF_INET, addr1, tmp) == 1)) {
		strcpy(addr4, addr1);
		return strlen(addr4);
	}
#endif
#endif

#if CONFIG_NET_IPV6
#ifdef CONFIG_POSIX_API
	if ((addr6 != NULL) && (inet_pton(AF_INET6, addr1, tmp) == 1)) {
		strcpy(addr6, addr1);
		return strlen(addr6);
	}
	if ((addr6 != NULL) && (ret > 1) && (inet_pton(AF_INET6, addr2, tmp) == 1)) {
		strcpy(addr6, addr2);
		return strlen(addr6);
	}
#else
	if ((addr6 != NULL) && (zsock_inet_pton(NET_AF_INET6, addr1, tmp) == 1)) {
		strcpy(addr6, addr1);
		return strlen(addr6);
	}
	if ((addr6 != NULL) && (ret > 1) &&
	    (zsock_inet_pton(NET_AF_INET6, addr2, tmp) == 1)) {
		strcpy(addr6, addr2);
		return strlen(addr6);
	}
#endif
#endif

	return -ENODATA;
}

#if CONFIG_NET_IPV4
int lte_ipv4_addr_add(const struct net_if *iface)
{
	int len;
	char ipv4_addr[NET_IPV4_ADDR_LEN] = { 0 };
	struct net_sockaddr addr = { 0 };
	struct net_if_addr *ifaddr = NULL;

	if (iface == NULL) {
		return -EINVAL;
	}

	len = ip_addr_get(ipv4_addr, NULL);
	if (len < 0) {
		return len;
	}

	if (!net_ipaddr_parse(ipv4_addr, len, &addr)) {
		return -EFAULT;
	}

	ifaddr = net_if_ipv4_addr_add((struct net_if *)iface,
				      &net_sin(&addr)->sin_addr,
				      NET_ADDR_MANUAL,
				      0);
	if (!ifaddr) {
		return -ENODEV;
	}

	ctx.ipv4_addr_current = net_sin(&addr)->sin_addr;
	ctx.ipv4_added = true;

	return 0;
}

int lte_ipv4_addr_remove(const struct net_if *iface)
{
	if (iface == NULL) {
		return -EINVAL;
	}

	if (!ctx.ipv4_added) {
		LOG_DBG("No IPv4 address to remove");
		return 0;
	}

	if (!net_if_ipv4_addr_rm((struct net_if *)iface, &ctx.ipv4_addr_current)) {
		return -EFAULT;
	}

	ctx.ipv4_added = false;

	return 0;
}
#endif

#if CONFIG_NET_IPV6
int lte_ipv6_addr_add(const struct net_if *iface)
{
	int len;
	char ipv6_addr[NET_IPV6_ADDR_LEN] = { 0 };
	struct net_sockaddr addr = { 0 };
	struct net_if_addr *ifaddr = NULL;

	if (iface == NULL) {
		return -EINVAL;
	}

	len = ip_addr_get(NULL, ipv6_addr);
	if (len < 0) {
		return len;
	}

	if (!net_ipaddr_parse(ipv6_addr, len, &addr)) {
		return -EFAULT;
	}

	ifaddr = net_if_ipv6_addr_add((struct net_if *)iface,
				      &net_sin6(&addr)->sin6_addr,
				      NET_ADDR_MANUAL,
				      0);
	if (!ifaddr) {
		return -ENODEV;
	}

	ctx.ipv6_addr_current = net_sin6(&addr)->sin6_addr;
	ctx.ipv6_added = true;

	return 0;
}

int lte_ipv6_addr_remove(const struct net_if *iface)
{
	if (iface == NULL) {
		return -EINVAL;
	}

	if (!ctx.ipv6_added) {
		LOG_DBG("No IPv6 address to remove");
		return 0;
	}

	if (!net_if_ipv6_addr_rm((struct net_if *)iface, &ctx.ipv6_addr_current)) {
		return -EFAULT;
	}

	ctx.ipv6_added = false;

	return 0;
}
#endif /* CONFIG_NET_IPV6 */
```

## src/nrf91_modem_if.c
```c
/*
 * Copyright (c) 2026 Nordic Semiconductor ASA
 *
 * SPDX-License-Identifier: LicenseRef-Nordic-5-Clause
 */

#include <zephyr/kernel.h>
#include <zephyr/random/random.h>
#include <zephyr/net/dummy.h>
#include <zephyr/net/net_pkt.h>
#include <zephyr/net/net_if.h>
#include <zephyr/net/net_ip.h>
#include <zephyr/net/dns_resolve.h>
#include <zephyr/posix/arpa/inet.h>
#include <modem/nrf_modem_lib.h>
#include <modem/lte_lc.h>
#include <errno.h>
#include <nrf_modem_at.h>
#include <nrf_socket.h>
#include <zephyr/logging/log.h>

#include "lte_ip_addr_helper.h"

LOG_MODULE_REGISTER(nrf91_modem_if, LOG_LEVEL_INF);

#define NO_MDM_SCKT 				(-1)
#define NRF91_MTU_DEFAULT			1500

#define NRF91_MODEM_DATA_UL_BUFFER_SIZE		1280
#define NRF91_MODEM_DATA_DL_BUFFER_SIZE 	1280

#define NRF91_MODEM_DATA_DL_THREAD_STACK_SIZE	1536
#define NRF91_MODEM_DATA_RCV_THREAD_PRIORITY	K_HIGHEST_APPLICATION_THREAD_PRIO

struct nrf91_modem_ctx {
	uint8_t mac_addr[6];
	struct net_if *iface;
	bool default_pdp_active;
	int mdm_skct_id;
};

static struct nrf91_modem_ctx nrf91_modem_ctx;

static char send_buffer[NRF91_MODEM_DATA_UL_BUFFER_SIZE];
static char receive_buffer[NRF91_MODEM_DATA_DL_BUFFER_SIZE];

static struct k_work_delayable mdm_socket_work;
static K_SEM_DEFINE(mdm_socket_sem, 0, 1);

static K_MUTEX_DEFINE(nr91_modem_ctx_lock);
static K_MUTEX_DEFINE(send_buf_lock);

/******************************************************************************/

static uint16_t pdn_mtu(void)
{
	struct lte_lc_pdn_dynamic_info info;
	int err;

	err = lte_lc_pdn_dynamic_info_get(0, &info);
	if ((err != 0) || (info.ipv4_mtu == 0)) {
		LOG_WRN("MTU query failed, error: %d, MTU: %d", err, info.ipv4_mtu);

		info.ipv4_mtu = NET_IPV4_MTU;
	}

	LOG_DBG("Network MTU: %d", info.ipv4_mtu);

	return (uint16_t)info.ipv4_mtu;
}

#if !defined(CONFIG_DNS_SERVER_IP_ADDRESSES)
static int util_get_dns_servers(int cid, struct in_addr *dns1, struct in_addr *dns2)
{
	int ret;
	char response[512];
	char dns1_str[NET_IPV4_ADDR_LEN] = { 0 };
	char dns2_str[NET_IPV4_ADDR_LEN] = { 0 };

	ret = nrf_modem_at_cmd(response, sizeof(response), "AT+CGCONTRDP=%d", cid);
	if (ret) {
		LOG_ERR("AT+CGCONTRDP failed: %d", ret);

		return -EIO;
	}

	ret = nrf_modem_at_scanf(response,
				 "+CGCONTRDP: %*d,%*d,%*[^,],%*[^,],%*[^,],%*[^,],"
				 "\"%15[.0-9]\",\"%15[.0-9]\"",
				 dns1_str, dns2_str);

	if (ret >= 1 && strlen(dns1_str) > 0) {
		if (inet_pton(AF_INET, dns1_str, dns1) == 1) {
			LOG_DBG("Primary DNS: %s", dns1_str);
		} else {
			return -EINVAL;
		}
	} else {
		return -ENOENT;
	}

	if (ret >= 2 && strlen(dns2_str) > 0) {
		inet_pton(AF_INET, dns2_str, dns2);
		LOG_DBG("Secondary DNS: %s", dns2_str);
	}

	return 0;
}

static void configure_dns_from_modem(int cid)
{
	int ret;
	struct in_addr dns1 = { 0 };
	struct in_addr dns2 = { 0 };
	struct dns_resolve_context *dnsctx;
	struct sockaddr_in dns_server1 = {
		.sin_family = AF_INET,
		.sin_port = htons(53),
		.sin_addr = dns1
	};
	struct sockaddr_in dns_server2 = {
		.sin_family = AF_INET,
		.sin_port = htons(53),
		.sin_addr = dns2
	};
	const struct sockaddr *dns_servers[] = {
		(struct sockaddr *)&dns_server1,
		(struct sockaddr *)&dns_server2,
		NULL
	};

	ret = util_get_dns_servers(cid, &dns1, &dns2);
	if (ret != 0) {
		return;
	}

	dnsctx = dns_resolve_get_default();

	ret = dns_resolve_reconfigure(dnsctx, NULL, dns_servers, DNS_SOURCE_MANUAL);
	if (ret < 0) {
		LOG_ERR("DNS reconfigure failed: %d", ret);
	}
}
#endif /* CONFIG_DNS_SERVER_IP_ADDRESSES */

static void on_pdn_activated(void)
{
	k_mutex_lock(&nr91_modem_ctx_lock, K_FOREVER);

	nrf91_modem_ctx.default_pdp_active = true;

	k_mutex_unlock(&nr91_modem_ctx_lock);

	k_work_schedule(&mdm_socket_work, K_SECONDS(2));
}

static void on_pdn_deactivated(void)
{
	k_mutex_lock(&nr91_modem_ctx_lock, K_FOREVER);

	nrf91_modem_ctx.default_pdp_active = false;

	k_mutex_unlock(&nr91_modem_ctx_lock);

	k_work_schedule(&mdm_socket_work, K_NO_WAIT);
}

#if CONFIG_NET_IPV6
static void on_pdn_ipv6_up(void)
{
	int ret;

	LOG_DBG("PDN IPv6 up");

	ret = lte_ipv6_addr_add(nrf91_modem_ctx.iface);
	if (ret && ret != -ENODATA) {
		LOG_ERR("lte_ipv6_addr_add failed: %d", ret);
	}
}

static void on_pdn_ipv6_down(void)
{
	int ret;

	LOG_DBG("PDN IPv6 down");

	ret = lte_ipv6_addr_remove(nrf91_modem_ctx.iface);
	if (ret) {
		LOG_ERR("lte_ipv6_addr_remove failed: %d", ret);
	}
}
#endif /* CONFIG_NET_IPV6 */

static void nrf91_lte_evt_handler(const struct lte_lc_evt *const evt)
{
	switch (evt->type) {
	case LTE_LC_EVT_PDN:
		if (evt->pdn.cid != 0) {
			break;
		}

		LOG_DBG("PDN event type: %d, cid: %d", evt->pdn.type, evt->pdn.cid);

		switch (evt->pdn.type) {
		case LTE_LC_EVT_PDN_ACTIVATED:
			on_pdn_activated();

			break;
		case LTE_LC_EVT_PDN_NETWORK_DETACH:
			__fallthrough;
		case LTE_LC_EVT_PDN_DEACTIVATED:
			on_pdn_deactivated();

			break;
#if CONFIG_NET_IPV6
		case LTE_LC_EVT_PDN_IPV6_UP:
			on_pdn_ipv6_up();

			break;
		case LTE_LC_EVT_PDN_IPV6_DOWN:
			on_pdn_ipv6_down();

			break;
#endif
		case LTE_LC_EVT_PDN_CTX_DESTROYED:
			LOG_DBG("PDN context destroyed");

			break;
		default:
			break;
		}
		break;
	default:
		break;
	}
}

static void nrf91_socket_create(void)
{
	int ret;

	ret = nrf_socket(NRF_AF_PACKET, NRF_SOCK_RAW, 0);
	if (ret < 0) {
		LOG_ERR("nrf_socket failed %d", ret);

		ret = NO_MDM_SCKT;

		k_sem_reset(&mdm_socket_sem);
	} else {
		k_sem_give(&mdm_socket_sem);
	}

	k_mutex_lock(&nr91_modem_ctx_lock, K_FOREVER);

	nrf91_modem_ctx.mdm_skct_id = ret;

	k_mutex_unlock(&nr91_modem_ctx_lock);
}

static void nrf91_socket_close(void)
{
	int ret;

	if (!nrf_modem_is_initialized()) {
		LOG_WRN("Modem not initialized, skipping socket close");

		return;
	}

	k_sem_reset(&mdm_socket_sem);
	nrf_close(nrf91_modem_ctx.mdm_skct_id);

	k_mutex_lock(&nr91_modem_ctx_lock, K_FOREVER);

	nrf91_modem_ctx.mdm_skct_id = NO_MDM_SCKT;

	k_mutex_unlock(&nr91_modem_ctx_lock);

#if CONFIG_NET_IPV4
	ret = lte_ipv4_addr_remove(nrf91_modem_ctx.iface);
	if (ret) {
		LOG_ERR("lte_ipv4_addr_remove failed: %d", ret);
	}
#endif
#if CONFIG_NET_IPV6
	ret = lte_ipv6_addr_remove(nrf91_modem_ctx.iface);
	if (ret) {
		LOG_ERR("lte_ipv6_addr_remove failed: %d", ret);
	}
#endif

	net_if_dormant_on(nrf91_modem_ctx.iface);
}

static void nrf91_mdm_socket_worker(struct k_work *unused)
{
	bool pdp_active;
	int socket_id;
	int ret;

	ARG_UNUSED(unused);

	k_mutex_lock(&nr91_modem_ctx_lock, K_FOREVER);

	pdp_active = nrf91_modem_ctx.default_pdp_active;
	socket_id = nrf91_modem_ctx.mdm_skct_id;

	k_mutex_unlock(&nr91_modem_ctx_lock);

	LOG_DBG("Socket worker running, pdp_active: %d, socket: %d", pdp_active, socket_id);

	if (!pdp_active) {
		nrf91_socket_close();

		return;
	}

	if (socket_id != NO_MDM_SCKT) {
		LOG_DBG("Modem socket already created");

		return;
	}

	LOG_DBG("Creating modem socket");
	nrf91_socket_create();

	k_mutex_lock(&nr91_modem_ctx_lock, K_FOREVER);

	socket_id = nrf91_modem_ctx.mdm_skct_id;

	k_mutex_unlock(&nr91_modem_ctx_lock);

	if (socket_id == NO_MDM_SCKT) {
		LOG_ERR("Socket creation failed");

		return;
	}

#if CONFIG_NET_IPV4
	ret = lte_ipv4_addr_add(nrf91_modem_ctx.iface);
	if (ret && ret != -ENODATA) {
		LOG_ERR("lte_ipv4_addr_add failed: %d", ret);

		return;
	}

	if (ret == -ENODATA) {
		LOG_WRN("No IPv4 address from network");
	}
#endif /* CONFIG_NET_IPV4 */

#if CONFIG_NET_IPV6
	ret = lte_ipv6_addr_add(nrf91_modem_ctx.iface);
	if (ret && ret != -ENODATA) {
		LOG_ERR("lte_ipv6_addr_add failed: %d", ret);

		return;
	}
#endif /* CONFIG_NET_IPV6 */

	net_if_set_mtu(nrf91_modem_ctx.iface, pdn_mtu());
	net_if_flag_set(nrf91_modem_ctx.iface, NET_IF_UP);
	net_if_dormant_off(nrf91_modem_ctx.iface);
	net_if_set_default(nrf91_modem_ctx.iface);
	net_mgmt_event_notify(NET_EVENT_L4_CONNECTED, nrf91_modem_ctx.iface);

#if defined(CONFIG_DNS_RESOLVER) && !defined(CONFIG_DNS_SERVER_IP_ADDRESSES)
	configure_dns_from_modem(0);
#endif
}

static uint8_t *util_fake_dev_get_mac(struct nrf91_modem_ctx *ctx)
{
	if (ctx->mac_addr[2] == 0x00) {
		/* 00-00-5E-00-53-xx Documentation RFC 7042 */
		ctx->mac_addr[0] = 0x00;
		ctx->mac_addr[1] = 0x00;
		ctx->mac_addr[2] = 0x5E;
		ctx->mac_addr[3] = 0x00;
		ctx->mac_addr[4] = 0x53;
		ctx->mac_addr[5] = sys_rand32_get();
	}

	return ctx->mac_addr;
}

static void nrf91_iface_init(struct net_if *iface)
{
	struct nrf91_modem_ctx *ctx = net_if_get_device(iface)->data;
	uint8_t *mac = util_fake_dev_get_mac(ctx);

	ctx->iface = iface;

	k_mutex_lock(&nr91_modem_ctx_lock, K_FOREVER);

	ctx->default_pdp_active = false;
	ctx->mdm_skct_id = NO_MDM_SCKT;

	k_mutex_unlock(&nr91_modem_ctx_lock);

	net_if_set_link_addr(iface, mac, 6, NET_LINK_ETHERNET);
	net_if_dormant_on(iface);

	LOG_DBG("Interface initialized in dormant state");
}

static int nrf91_init(const struct device *arg)
{
	ARG_UNUSED(arg);

	k_work_init_delayable(&mdm_socket_work, nrf91_mdm_socket_worker);
	lte_lc_register_handler(nrf91_lte_evt_handler);

	return 0;
}

static int nrf91_modem_send(const struct device *dev, struct net_pkt *pkt)
{
	int ret, data_len;

	k_mutex_lock(&send_buf_lock, K_FOREVER);

	data_len = net_pkt_get_len(pkt);

	ret = net_pkt_read(pkt, send_buffer, data_len);
	if (ret < 0) {
		LOG_ERR("Cannot read packet: %d", ret);
	} else {
		int socket_id;

		k_mutex_lock(&nr91_modem_ctx_lock, K_FOREVER);

		socket_id = ((struct nrf91_modem_ctx *)dev->data)->mdm_skct_id;

		k_mutex_unlock(&nr91_modem_ctx_lock);

		if (socket_id < 0) {
			LOG_ERR("No modem socket for send");

			ret = -ENETDOWN;
		} else {
			ret = nrf_send(socket_id, send_buffer, data_len, 0);
			if (ret < 0) {
				LOG_ERR("send() failed: (%d), data len: %d", -errno, data_len);
			} else if (ret != data_len) {
				LOG_ERR("Only partially sent: %d of %d", ret, data_len);
			}
		}
	}

	net_pkt_unref(pkt);
	k_mutex_unlock(&send_buf_lock);

	return ret;
}

static void nrf91_modem_recv_thread(void)
{
	struct net_pkt *rcv_pkt;
	int ret;
	int recv_data_len;
	int socket_id;

	while (true) {
		uint8_t ip_version;
		sa_family_t family;

		k_mutex_lock(&nr91_modem_ctx_lock, K_FOREVER);

		socket_id = nrf91_modem_ctx.mdm_skct_id;

		k_mutex_unlock(&nr91_modem_ctx_lock);

		if (socket_id < 0) {
			k_sem_take(&mdm_socket_sem, K_FOREVER);

			continue;
		}

		recv_data_len = nrf_recv(socket_id, receive_buffer, sizeof(receive_buffer), 0);
		if (recv_data_len > 0) {
			ip_version = (receive_buffer[0] >> 4) & 0x0F;
			if (ip_version == 4) {
				family = AF_INET;
			} else if (ip_version == 6) {
				family = AF_INET6;
			} else {
				LOG_ERR("Invalid IP version: %d", ip_version);

				continue;
			}

			rcv_pkt = net_pkt_rx_alloc_with_buffer(nrf91_modem_ctx.iface, recv_data_len,
							       family, 0, K_NO_WAIT);
			if (!rcv_pkt) {
				LOG_ERR("Cannot allocate rcv packet");
				k_sleep(K_MSEC(200));

				continue;
			}

			if (net_pkt_write(rcv_pkt, (uint8_t *)receive_buffer, recv_data_len)) {
				LOG_ERR("Cannot write pkt - dropped packet");
				net_pkt_unref(rcv_pkt);
			} else {
				ret = net_recv_data(nrf91_modem_ctx.iface, rcv_pkt);
				if (ret < 0) {
					LOG_ERR("Packet dropped by NET stack: %d", ret);
					net_pkt_unref(rcv_pkt);
				}
			}
		} else {
			LOG_WRN("nrf_recv() failed, error: %d", -errno);
		}
	}
}

K_THREAD_DEFINE(nrf91_modem_dl_data_thread, NRF91_MODEM_DATA_DL_THREAD_STACK_SIZE,
		nrf91_modem_recv_thread, NULL, NULL, NULL,
		NRF91_MODEM_DATA_RCV_THREAD_PRIORITY, 0, 0);

/******************************************************************************/

static struct dummy_api nrf91_modem_if_api = {
	.iface_api.init = nrf91_iface_init,
	.send = nrf91_modem_send,
};

/* Set up a dummy L2 per Zephyr requirement, as the real L2 lives in the modem */
#define NRF91_L2_LAYER		DUMMY_L2
#define NRF91_L2_CTX_TYPE	NET_L2_GET_CTX_TYPE(DUMMY_L2)

NET_DEVICE_INIT(nrf91_modem_if, "nrf91_modem_if_dev",
		nrf91_init, NULL,
		&nrf91_modem_ctx, NULL, CONFIG_KERNEL_INIT_PRIORITY_DEFAULT,
		&nrf91_modem_if_api, NRF91_L2_LAYER, NRF91_L2_CTX_TYPE,
		NRF91_MTU_DEFAULT);
```
